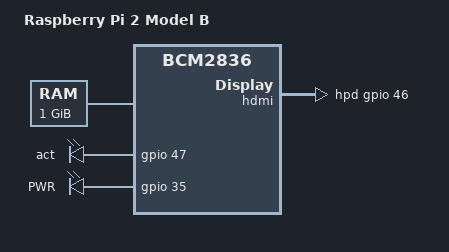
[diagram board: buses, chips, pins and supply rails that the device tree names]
/dts-v1/;
#include <dt-bindings/gpio/gpio.h>
#include "bcm2836.dtsi"
#include "bcm2835-rpi.dtsi"

/ {
	compatible = "raspberrypi,2-model-b", "brcm,bcm2836";
	model = "Raspberry Pi 2 Model B";

	memory {
		reg = <0 0x40000000>;
	};

	leds {
		act {
			gpios = <&gpio 47 0>;
		};

		pwr {
			label = "PWR";
			gpios = <&gpio 35 0>;
			default-state = "keep";
			linux,default-trigger = "default-on";
		};
	};
	
	soc {
		pixelvalve@7e206000 {
			compatible = "brcm,bcm2835-pixelvalve0";
			reg = <0x7e206000 0x100>;
			interrupts = <2 13>; /* pwa0 */
		};
		
		pixelvalve@7e207000 {
			compatible = "brcm,bcm2835-pixelvalve1";
			reg = <0x7e207000 0x100>;
			interrupts = <2 14>; /* pwa1 */
		};
		
		pixelvalve@7e807000 {
			compatible = "brcm,bcm2835-pixelvalve2";
			reg = <0x7e807000 0x100>;
			interrupts = <2 10>; /* pixelvalve */
		};
		
		hvs@7e400000 {
			compatible = "brcm,bcm2835-hvs";
			reg = <0x7e400000 0x6000>;
			interrupts = <2 1>;
		};
		
		hdmi: hdmi@7e902000 {
			compatible = "brcm,bcm2835-hdmi";
			reg = <0x7e902000 0x600>,
			      <0x7e808000 0x100>;
			interrupts = <2 8>, <2 9>;
			ddc = <&i2c2>;
			hpd-gpios = <&gpio 46 GPIO_ACTIVE_HIGH>;
			clocks = <&clocks BCM2835_PLLH_PIX>,
				 <&clocks BCM2835_CLOCK_HSM>;
			clock-names = "pixel", "hdmi";
		};
		
		v3d: v3d@7ec00000 {
			compatible = "brcm,bcm2835-v3d";
			reg = <0x7ec00000 0x1000>;
			interrupts = <1 10>;
		};
		
		vc4: gpu@7e4c0000 {
			compatible = "brcm,bcm2835-vc4";
		};
	};
};

&gpio {
	pinctrl-0 = <&gpioout &alt0 &i2s_alt0 &alt3>;

	/* I2S interface */
	i2s_alt0: i2s_alt0 {
		brcm,pins = <18 19 20 21>;
		brcm,function = <BCM2835_FSEL_ALT0>;
	};
};
